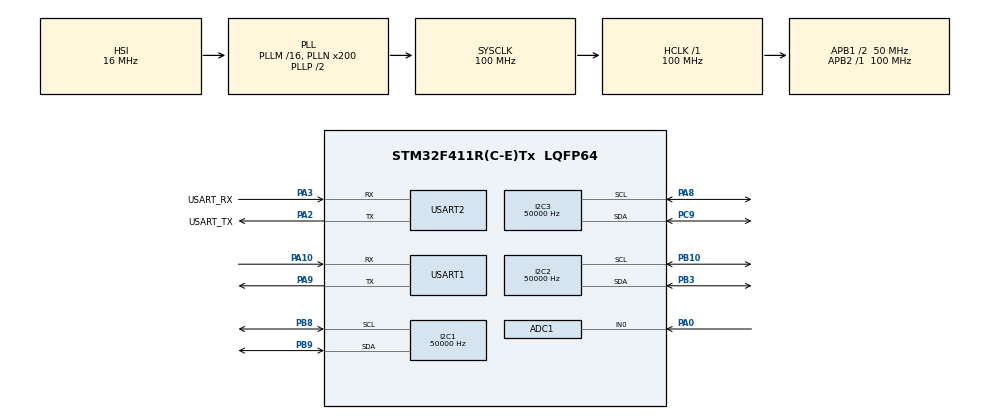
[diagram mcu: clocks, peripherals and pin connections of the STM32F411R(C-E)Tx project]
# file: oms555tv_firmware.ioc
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ADC1.Channel-0\#ChannelRegularConversion=ADC_CHANNEL_0
ADC1.NbrOfConversionFlag=1
ADC1.Rank-0\#ChannelRegularConversion=1
ADC1.SamplingTime-0\#ChannelRegularConversion=ADC_SAMPLETIME_84CYCLES
ADC1.master=1
I2C1.ClockSpeed=50000
I2C2.ClockSpeed=50000
I2C3.ClockSpeed=50000
Mcu.Family=STM32F4
Mcu.Name=STM32F411R(C-E)Tx
Mcu.Package=LQFP64
NVIC.PriorityGroup=NVIC_PRIORITYGROUP_0
NVIC.USART1_IRQn=true\:0\:0\:false\:false\:true\:true\:true\:true
NVIC.USART2_IRQn=true\:0\:0\:false\:false\:true\:true\:true\:true
PA0-WKUP.Signal=ADCx_IN0
PA13.GPIO_Label=TMS
PA13.Mode=Serial_Wire
PA13.Signal=SYS_JTMS-SWDIO
PA14.GPIO_Label=TCK
PA14.Mode=Serial_Wire
PA14.Signal=SYS_JTCK-SWCLK
PA2.GPIO_Label=USART_TX
PA2.Mode=Asynchronous
PA2.Signal=USART2_TX
PA3.GPIO_Label=USART_RX
PA3.Mode=Asynchronous
PA3.Signal=USART2_RX
PA8.Mode=I2C
PA8.Signal=I2C3_SCL
PA9.Mode=Asynchronous
PA9.Signal=USART1_TX
PA10.Mode=Asynchronous
PA10.Signal=USART1_RX
PB10.Mode=I2C
PB10.Signal=I2C2_SCL
PB3.Mode=I2C
PB3.Signal=I2C2_SDA
PB8.Mode=I2C
PB8.Signal=I2C1_SCL
PB9.Mode=I2C
PB9.Signal=I2C1_SDA
PC9.Mode=I2C
PC9.Signal=I2C3_SDA
ProjectManager.HeapSize=0x200
ProjectManager.StackSize=0x400
ProjectManager.TargetToolchain=CMake
RCC.48MHZClocksFreq_Value=50000000
RCC.AHBFreq_Value=100000000
RCC.APB1CLKDivider=RCC_HCLK_DIV2
RCC.APB1Freq_Value=50000000
RCC.APB1TimFreq_Value=100000000
RCC.APB2Freq_Value=100000000
RCC.APB2TimFreq_Value=100000000
RCC.CortexFreq_Value=100000000
RCC.FLatency-AdvancedSettings=FLASH_LATENCY_3
RCC.HCLKFreq_Value=100000000
RCC.HSE_VALUE=25000000
RCC.HSI_VALUE=16000000
RCC.LSE_VALUE=32768
RCC.PLLM=16
RCC.PLLN=200
RCC.PLLP=RCC_PLLP_DIV2
RCC.SYSCLKFreq_VALUE=100000000
RCC.SYSCLKSource=RCC_SYSCLKSOURCE_PLLCLK
RCC.VCOOutputFreq_Value=200000000
SH.ADCx_IN0.0=ADC1_IN0,IN0
SYS.Debug=Serial Wire
USART1.VirtualMode=VM_ASYNC
USART2.VirtualMode=VM_ASYNC
board=NUCLEO-F411RE

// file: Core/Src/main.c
/* USER CODE BEGIN Header */
/**
  ******************************************************************************
  * @file           : main.c
  * @brief          : Main program body
  ******************************************************************************
  * @attention
  *
  * Copyright (c) 2026 STMicroelectronics.
  * All rights reserved.
  *
  * This software is licensed under terms that can be found in the LICENSE file
  * in the root directory of this software component.
  * If no LICENSE file comes with this software, it is provided AS-IS.
  *
  ******************************************************************************
  */
/* USER CODE END Header */
#include "main.h"

/* USER CODE BEGIN Includes */
#include "app.h"
/* USER CODE END Includes */

ADC_HandleTypeDef hadc1;

I2C_HandleTypeDef hi2c1;
I2C_HandleTypeDef hi2c2;
I2C_HandleTypeDef hi2c3;

UART_HandleTypeDef huart1;
UART_HandleTypeDef huart2;

void SystemClock_Config(void);
static void MX_GPIO_Init(void);
static void MX_I2C1_Init(void);
static void MX_I2C2_Init(void);
static void MX_I2C3_Init(void);
static void MX_USART1_UART_Init(void);
static void MX_USART2_UART_Init(void);
static void MX_ADC1_Init(void);

int main(void)
{

  /* MCU Configuration--------------------------------------------------------*/

  /* Reset of all peripherals, Initializes the Flash interface and the Systick. */
  HAL_Init();

  /* Configure the system clock */
  SystemClock_Config();

  /* Initialize all configured peripherals */
  MX_GPIO_Init();
  MX_I2C1_Init();
  MX_I2C2_Init();
  MX_I2C3_Init();
  MX_USART1_UART_Init();
  MX_USART2_UART_Init();
  MX_ADC1_Init();
  /* USER CODE BEGIN 2 */
  if (!app_init())
  {
    Error_Handler();
  }
/* USER CODE END 2 */

  /* Infinite loop */
  while (1)
  {

    /* USER CODE BEGIN 3 */
    app_service();
  }
  /* USER CODE END 3 */
}

void SystemClock_Config(void)
{
  RCC_OscInitTypeDef RCC_OscInitStruct = {0};
  RCC_ClkInitTypeDef RCC_ClkInitStruct = {0};

  /** Configure the main internal regulator output voltage
  */
  __HAL_RCC_PWR_CLK_ENABLE();
  __HAL_PWR_VOLTAGESCALING_CONFIG(PWR_REGULATOR_VOLTAGE_SCALE1);

  /** Initializes the RCC Oscillators according to the specified parameters
  * in the RCC_OscInitTypeDef structure.
  */
  RCC_OscInitStruct.OscillatorType = RCC_OSCILLATORTYPE_HSI;
  RCC_OscInitStruct.HSIState = RCC_HSI_ON;
  RCC_OscInitStruct.HSICalibrationValue = RCC_HSICALIBRATION_DEFAULT;
  RCC_OscInitStruct.PLL.PLLState = RCC_PLL_ON;
  RCC_OscInitStruct.PLL.PLLSource = RCC_PLLSOURCE_HSI;
  RCC_OscInitStruct.PLL.PLLM = 16;
  RCC_OscInitStruct.PLL.PLLN = 200;
  RCC_OscInitStruct.PLL.PLLP = RCC_PLLP_DIV2;
  RCC_OscInitStruct.PLL.PLLQ = 4;
  if (HAL_RCC_OscConfig(&RCC_OscInitStruct) != HAL_OK)
  {
    Error_Handler();
  }

  /** Initializes the CPU, AHB and APB buses clocks
  */
  RCC_ClkInitStruct.ClockType = RCC_CLOCKTYPE_HCLK|RCC_CLOCKTYPE_SYSCLK
                              |RCC_CLOCKTYPE_PCLK1|RCC_CLOCKTYPE_PCLK2;
  RCC_ClkInitStruct.SYSCLKSource = RCC_SYSCLKSOURCE_PLLCLK;
  RCC_ClkInitStruct.AHBCLKDivider = RCC_SYSCLK_DIV1;
  RCC_ClkInitStruct.APB1CLKDivider = RCC_HCLK_DIV2;
  RCC_ClkInitStruct.APB2CLKDivider = RCC_HCLK_DIV1;

  if (HAL_RCC_ClockConfig(&RCC_ClkInitStruct, FLASH_LATENCY_3) != HAL_OK)
  {
    Error_Handler();
  }
}

static void MX_ADC1_Init(void)
{

  ADC_ChannelConfTypeDef sConfig = {0};

  /** Configure the global features of the ADC (Clock, Resolution, Data Alignment and number of conversion)
  */
  hadc1.Instance = ADC1;
  hadc1.Init.ClockPrescaler = ADC_CLOCK_SYNC_PCLK_DIV4;
  hadc1.Init.Resolution = ADC_RESOLUTION_12B;
  hadc1.Init.ScanConvMode = DISABLE;
  hadc1.Init.ContinuousConvMode = DISABLE;
  hadc1.Init.DiscontinuousConvMode = DISABLE;
  hadc1.Init.ExternalTrigConvEdge = ADC_EXTERNALTRIGCONVEDGE_NONE;
  hadc1.Init.ExternalTrigConv = ADC_SOFTWARE_START;
  hadc1.Init.DataAlign = ADC_DATAALIGN_RIGHT;
  hadc1.Init.NbrOfConversion = 1;
  hadc1.Init.DMAContinuousRequests = DISABLE;
  hadc1.Init.EOCSelection = ADC_EOC_SINGLE_CONV;
  if (HAL_ADC_Init(&hadc1) != HAL_OK)
  {
    Error_Handler();
  }

  /** Configure for the selected ADC regular channel its corresponding rank in the sequencer and its sample time.
  */
  sConfig.Channel = ADC_CHANNEL_0;
  sConfig.Rank = 1;
  sConfig.SamplingTime = ADC_SAMPLETIME_84CYCLES;
  if (HAL_ADC_ConfigChannel(&hadc1, &sConfig) != HAL_OK)
  {
    Error_Handler();
  }

}

static void MX_I2C1_Init(void)
{

  hi2c1.Instance = I2C1;
  hi2c1.Init.ClockSpeed = 50000;
  hi2c1.Init.DutyCycle = I2C_DUTYCYCLE_2;
  hi2c1.Init.OwnAddress1 = 0;
  hi2c1.Init.AddressingMode = I2C_ADDRESSINGMODE_7BIT;
  hi2c1.Init.DualAddressMode = I2C_DUALADDRESS_DISABLE;
  hi2c1.Init.OwnAddress2 = 0;
  hi2c1.Init.GeneralCallMode = I2C_GENERALCALL_DISABLE;
  hi2c1.Init.NoStretchMode = I2C_NOSTRETCH_DISABLE;
  if (HAL_I2C_Init(&hi2c1) != HAL_OK)
  {
    Error_Handler();
  }

}

static void MX_I2C2_Init(void)
{

  hi2c2.Instance = I2C2;
  hi2c2.Init.ClockSpeed = 50000;
  hi2c2.Init.DutyCycle = I2C_DUTYCYCLE_2;
  hi2c2.Init.OwnAddress1 = 0;
  hi2c2.Init.AddressingMode = I2C_ADDRESSINGMODE_7BIT;
  hi2c2.Init.DualAddressMode = I2C_DUALADDRESS_DISABLE;
  hi2c2.Init.OwnAddress2 = 0;
  hi2c2.Init.GeneralCallMode = I2C_GENERALCALL_DISABLE;
  hi2c2.Init.NoStretchMode = I2C_NOSTRETCH_DISABLE;
  if (HAL_I2C_Init(&hi2c2) != HAL_OK)
  {
    Error_Handler();
  }

}

static void MX_I2C3_Init(void)
{

  hi2c3.Instance = I2C3;
  hi2c3.Init.ClockSpeed = 50000;
  hi2c3.Init.DutyCycle = I2C_DUTYCYCLE_2;
  hi2c3.Init.OwnAddress1 = 0;
  hi2c3.Init.AddressingMode = I2C_ADDRESSINGMODE_7BIT;
  hi2c3.Init.DualAddressMode = I2C_DUALADDRESS_DISABLE;
  hi2c3.Init.OwnAddress2 = 0;
  hi2c3.Init.GeneralCallMode = I2C_GENERALCALL_DISABLE;
  hi2c3.Init.NoStretchMode = I2C_NOSTRETCH_DISABLE;
  if (HAL_I2C_Init(&hi2c3) != HAL_OK)
  {
    Error_Handler();
  }

}

static void MX_USART1_UART_Init(void)
{

  huart1.Instance = USART1;
  huart1.Init.BaudRate = 115200;
  huart1.Init.WordLength = UART_WORDLENGTH_8B;
  huart1.Init.StopBits = UART_STOPBITS_1;
  huart1.Init.Parity = UART_PARITY_NONE;
  huart1.Init.Mode = UART_MODE_TX_RX;
  huart1.Init.HwFlowCtl = UART_HWCONTROL_NONE;
  huart1.Init.OverSampling = UART_OVERSAMPLING_16;
  if (HAL_UART_Init(&huart1) != HAL_OK)
  {
    Error_Handler();
  }

}

static void MX_USART2_UART_Init(void)
{

  huart2.Instance = USART2;
  huart2.Init.BaudRate = 115200;
  huart2.Init.WordLength = UART_WORDLENGTH_8B;
  huart2.Init.StopBits = UART_STOPBITS_1;
  huart2.Init.Parity = UART_PARITY_NONE;
  huart2.Init.Mode = UART_MODE_TX_RX;
  huart2.Init.HwFlowCtl = UART_HWCONTROL_NONE;
  huart2.Init.OverSampling = UART_OVERSAMPLING_16;
  if (HAL_UART_Init(&huart2) != HAL_OK)
  {
    Error_Handler();
  }

}

static void MX_GPIO_Init(void)
{

  /* GPIO Ports Clock Enable */
  __HAL_RCC_GPIOA_CLK_ENABLE();
  __HAL_RCC_GPIOB_CLK_ENABLE();
  __HAL_RCC_GPIOC_CLK_ENABLE();

}

void Error_Handler(void)
{
  __disable_irq();
  while (1)
  {
  }
}
